AUTOSAR XML (schema 4-3-0)
package /Dimmer
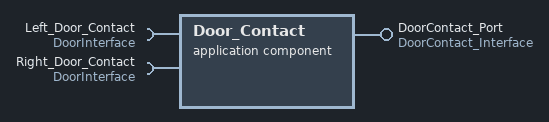
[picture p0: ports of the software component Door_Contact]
  application sw component type Door_Contact
    require port Left_Door_Contact: nonqueued-receiver-com-spec=DoorStatus, required-interface=DoorInterface
    require port Right_Door_Contact: nonqueued-receiver-com-spec=DoorStatus, required-interface=DoorInterface
    provide port DoorContact_Port: nonqueued-sender-com-spec=DoorContact_Status, provided-interface=DoorContact_Interface
    behavior Door_Contact_InternalBehavior
  swc implementation Door_Contact_Implementation: behavior=Door_Contact_InternalBehavior
